# TM4C129CNCZAD register map
Vendor: Texas Instruments; Series: TM4C; File version: 12591
CPU: CM4 r1p2, little endian, no MPU, FPU, 3 interrupt priority bits
Registers are 32-bit, read-write, no defined reset value unless marked. A register's access mark holds for its fields unless they carry their own. Offsets are from the block's base; [hi:lo] are bit positions; {n}, {i} and the like mark numbered series.

## EEPROM — Register map for EEPROM peripheral
Base 0x400AF000; register names take the prefix EEPROM
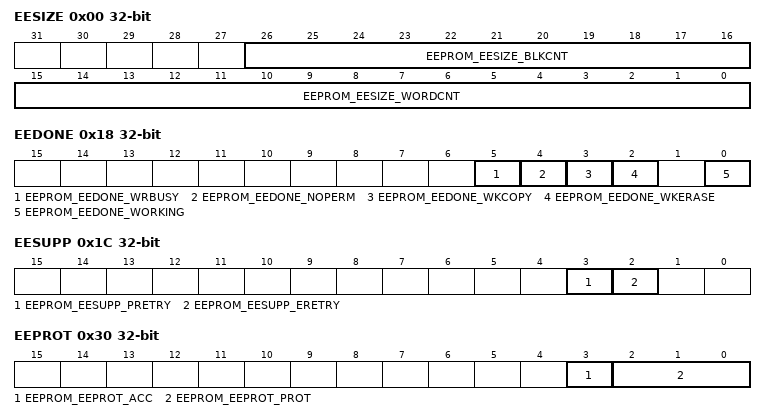
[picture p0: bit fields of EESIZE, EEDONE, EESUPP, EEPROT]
0x00 EESIZE — EEPROM Size Information
  [26:16] EEPROM_EESIZE_BLKCNT — Number of 16-Word Blocks
  [15:0] EEPROM_EESIZE_WORDCNT — Number of 32-Bit Words
0x04 EEBLOCK — EEPROM Current Block
  [15:0] EEPROM_EEBLOCK_BLOCK — Current Block
0x08 EEOFFSET — EEPROM Current Offset
  [3:0] EEPROM_EEOFFSET_OFFSET — Current Address Offset
0x10 EERDWR — EEPROM Read-Write
  [31:0] EEPROM_EERDWR_VALUE — EEPROM Read or Write Data
0x14 EERDWRINC — EEPROM Read-Write with Increment
  [31:0] EEPROM_EERDWRINC_VALUE — EEPROM Read or Write Data with Increment
0x18 EEDONE — EEPROM Done Status
  [5] EEPROM_EEDONE_WRBUSY — Write Busy
  [4] EEPROM_EEDONE_NOPERM — Write Without Permission
  [3] EEPROM_EEDONE_WKCOPY — Working on a Copy
  [2] EEPROM_EEDONE_WKERASE — Working on an Erase
  [0] EEPROM_EEDONE_WORKING — EEPROM Working
0x1C EESUPP — EEPROM Support Control and Status
  [3] EEPROM_EESUPP_PRETRY — Programming Must Be Retried
  [2] EEPROM_EESUPP_ERETRY — Erase Must Be Retried
0x20 EEUNLOCK — EEPROM Unlock
  [31:0] EEPROM_EEUNLOCK_UNLOCK
0x30 EEPROT — EEPROM Protection
  [3] EEPROM_EEPROT_ACC — Access Control
  [2:0] EEPROM_EEPROT_PROT — Protection Control
    0=EEPROM_EEPROT_PROT_RWNPW (This setting is the default. If there is no password, the block is not protected and is readable and writable); 1=EEPROM_EEPROT_PROT_RWPW (If there is a password, the block is readable or writable only when unlocked); 2=EEPROM_EEPROT_PROT_RONPW (If there is no password, the block is readable, not writable)
{0x34+4i} EEPASS{i} (i=0..2) — EEPROM Password
  [31:0] EEPROM_EEPASS{i}_PASS — Password
0x40 EEINT — EEPROM Interrupt
  [0] EEPROM_EEINT_INT — Interrupt Enable
0x50 EEHIDE0 — EEPROM Block Hide 0
  [31:1] EEPROM_EEHIDE0_HN — Hide Block
0x54 EEHIDE1 — EEPROM Block Hide 1
  [31:0] EEPROM_EEHIDE1_HN — Hide Block
0x58 EEHIDE2 — EEPROM Block Hide 2
  [31:0] EEPROM_EEHIDE2_HN — Hide Block
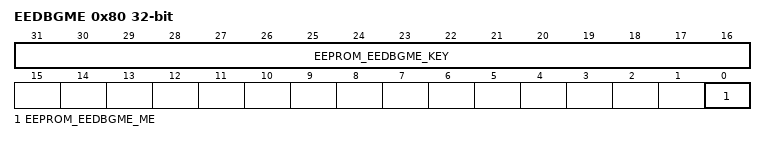
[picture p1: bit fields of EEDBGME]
0x80 EEDBGME — EEPROM Debug Mass Erase
  [31:16] EEPROM_EEDBGME_KEY — Erase Key
  [0] EEPROM_EEDBGME_ME — Mass Erase
0xFC0 PP — EEPROM Peripheral Properties
  [15:0] EEPROM_PP_SIZE — EEPROM Size
    0=64 bytes of EEPROM; 1=128 bytes of EEPROM; 3=256 bytes of EEPROM; 7=512 bytes of EEPROM; 15=EEPROM_PP_SIZE_1K (1 KB of EEPROM); 31=EEPROM_PP_SIZE_2K (2 KB of EEPROM); 63=EEPROM_PP_SIZE_3K (3 KB of EEPROM); 127=EEPROM_PP_SIZE_4K (4 KB of EEPROM); 255=EEPROM_PP_SIZE_5K (5 KB of EEPROM); 0x1FF=EEPROM_PP_SIZE_6K (6 KB of EEPROM)

## SYSEXC — Register map for SYSEXC peripheral
Base 0x400F9000; register names take the prefix SYSEXC
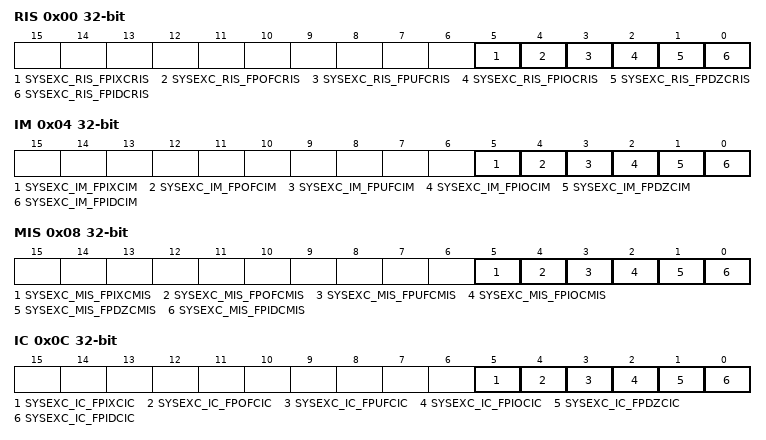
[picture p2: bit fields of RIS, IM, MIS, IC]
0x00 RIS — System Exception Raw Interrupt Status
  [5] SYSEXC_RIS_FPIXCRIS — Floating-Point Inexact Exception Raw Interrupt Status
  [4] SYSEXC_RIS_FPOFCRIS — Floating-Point Overflow Exception Raw Interrupt Status
  [3] SYSEXC_RIS_FPUFCRIS — Floating-Point Underflow Exception Raw Interrupt Status
  [2] SYSEXC_RIS_FPIOCRIS — Floating-Point Invalid Operation Raw Interrupt Status
  [1] SYSEXC_RIS_FPDZCRIS — Floating-Point Divide By 0 Exception Raw Interrupt Status
  [0] SYSEXC_RIS_FPIDCRIS — Floating-Point Input Denormal Exception Raw Interrupt Status
0x04 IM — System Exception Interrupt Mask
  [5] SYSEXC_IM_FPIXCIM — Floating-Point Inexact Exception Interrupt Mask
  [4] SYSEXC_IM_FPOFCIM — Floating-Point Overflow Exception Interrupt Mask
  [3] SYSEXC_IM_FPUFCIM — Floating-Point Underflow Exception Interrupt Mask
  [2] SYSEXC_IM_FPIOCIM — Floating-Point Invalid Operation Interrupt Mask
  [1] SYSEXC_IM_FPDZCIM — Floating-Point Divide By 0 Exception Interrupt Mask
  [0] SYSEXC_IM_FPIDCIM — Floating-Point Input Denormal Exception Interrupt Mask
0x08 MIS — System Exception Masked Interrupt Status
  [5] SYSEXC_MIS_FPIXCMIS — Floating-Point Inexact Exception Masked Interrupt Status
  [4] SYSEXC_MIS_FPOFCMIS — Floating-Point Overflow Exception Masked Interrupt Status
  [3] SYSEXC_MIS_FPUFCMIS — Floating-Point Underflow Exception Masked Interrupt Status
  [2] SYSEXC_MIS_FPIOCMIS — Floating-Point Invalid Operation Masked Interrupt Status
  [1] SYSEXC_MIS_FPDZCMIS — Floating-Point Divide By 0 Exception Masked Interrupt Status
  [0] SYSEXC_MIS_FPIDCMIS — Floating-Point Input Denormal Exception Masked Interrupt Status
0x0C IC wo — System Exception Interrupt Clear
  [5] SYSEXC_IC_FPIXCIC — Floating-Point Inexact Exception Interrupt Clear
  [4] SYSEXC_IC_FPOFCIC — Floating-Point Overflow Exception Interrupt Clear
  [3] SYSEXC_IC_FPUFCIC — Floating-Point Underflow Exception Interrupt Clear
  [2] SYSEXC_IC_FPIOCIC — Floating-Point Invalid Operation Interrupt Clear
  [1] SYSEXC_IC_FPDZCIC — Floating-Point Divide By 0 Exception Interrupt Clear
  [0] SYSEXC_IC_FPIDCIC — Floating-Point Input Denormal Exception Interrupt Clear

## Notices in the file
Software License Agreement
Texas Instruments (TI) is supplying this software for use solely and
exclusively on TI's microcontroller products. The software is owned by
TI and/or its suppliers, and is protected under applicable copyright
laws. You may not combine this software with "viral" open-source
software in order to form a larger program.
THIS SOFTWARE IS PROVIDED "AS IS" AND WITH ALL FAULTS.
NO WARRANTIES, WHETHER EXPRESS, IMPLIED OR STATUTORY, INCLUDING, BUT
NOT LIMITED TO, IMPLIED WARRANTIES OF MERCHANTABILITY AND FITNESS FOR
A PARTICULAR PURPOSE APPLY TO THIS SOFTWARE. TI SHALL NOT, UNDER ANY
CIRCUMSTANCES, BE LIABLE FOR SPECIAL, INCIDENTAL, OR CONSEQUENTIAL
DAMAGES, FOR ANY REASON WHATSOEVER.
